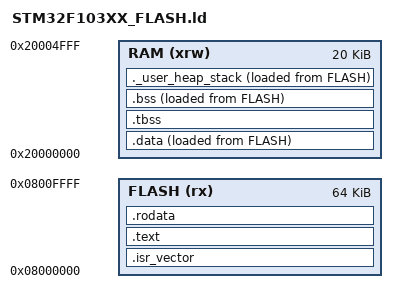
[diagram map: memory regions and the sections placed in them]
/* Entry Point */
ENTRY(Reset_Handler)

/* Specify the memory areas */
MEMORY
{
FLASH (rx)     : ORIGIN = 0x08000000, LENGTH = 64K
RAM (xrw)      : ORIGIN = 0x20000000, LENGTH = 20K
}

/* Highest address of the user mode stack */
_estack = ORIGIN(RAM) + LENGTH(RAM);    /* end of RAM */
/* Generate a link error if heap and stack don't fit into RAM */
_Min_Heap_Size = 0x400;      /* required amount of heap  */
_Min_Stack_Size = 0x400; /* required amount of stack */

/* Define output sections */
SECTIONS
{
  /* The startup code goes first into FLASH */
  .isr_vector :
  {
    . = ALIGN(4);
    KEEP(*(.isr_vector)) /* Startup code */
    . = ALIGN(4);
  } >FLASH

  /* The program code and other data goes into FLASH */
  .text :
  {
    . = ALIGN(4);
    *(.text)           /* .text sections (code) */
    *(.text*)          /* .text* sections (code) */
    *(.glue_7)         /* glue arm to thumb code */
    *(.glue_7t)        /* glue thumb to arm code */

    . = ALIGN(4);
    _etext = .;        /* define a global symbols at end of code */
  } >FLASH

  /* Constant data goes into FLASH */
  .rodata :
  {
    . = ALIGN(4);
    *(.rodata)         /* .rodata sections (constants, strings, etc.) */
    *(.rodata*)        /* .rodata* sections (constants, strings, etc.) */
    . = ALIGN(4);
  } >FLASH

  /* used by the startup to initialize data */
  _sidata = LOADADDR(.data);

  /* Initialized data sections goes into RAM, load LMA copy after code */
  .data :
  {
    . = ALIGN(4);
    _sdata = .;        /* create a global symbol at data start */
    *(.data)           /* .data sections */
    *(.data*)          /* .data* sections */
    *(.RamFunc)        /* .RamFunc sections */
    *(.RamFunc*)       /* .RamFunc* sections */

    . = ALIGN(4);
    _edata = .;        /* define a global symbol at data end */
    PROVIDE(__data_end = .);
  } >RAM AT> FLASH

  PROVIDE( __data_start = ADDR(.data) );
  PROVIDE( __data_size = __data_end - __data_start );

  PROVIDE( __data_source = LOADADDR(.data) );
  PROVIDE( __data_source_end = LOADADDR(.data) + SIZEOF(.data) );
  PROVIDE( __data_source_size = __data_source_end - __data_source );
  
  /* Uninitialized data section */
  /* unused section for CXX TLS feature but fail to remove related code */
  .tbss (NOLOAD) : ALIGN(4)
  {
    *(.tbss .tbss.*)
  } >RAM

  .bss (NOLOAD) : ALIGN(4)
  {
     /* This is used by the startup in order to initialize the .bss secion */
    _sbss = .;         /* define a global symbol at bss start */
    __bss_start__ = _sbss;
    *(.bss)
    *(.bss*)
    *(COMMON)

    . = ALIGN(4);
    _ebss = .;         /* define a global symbol at bss end */
    __bss_end__ = _ebss;
      PROVIDE( __bss_end = .);
  } >RAM AT> FLASH

  PROVIDE( __bss_start = ADDR(.bss) );
  PROVIDE( __bss_size = __bss_end - __bss_start );

  /* User_heap_stack section, used to check that there is enough RAM left */
  ._user_heap_stack (NOLOAD) :
  {
    . = ALIGN(8);
    PROVIDE ( end = . );
    PROVIDE ( _end = . );
    . = . + _Min_Heap_Size;
    . = . + _Min_Stack_Size;
    . = ALIGN(8);
  } >RAM AT> FLASH

  /DISCARD/ :
  {
    *(.ARM.exidx*)
  }
}
